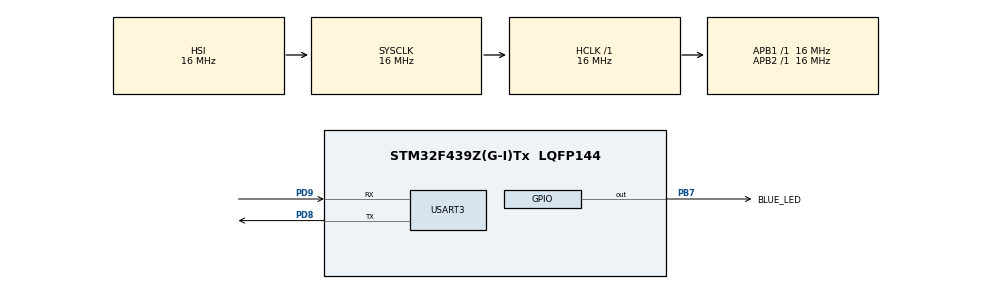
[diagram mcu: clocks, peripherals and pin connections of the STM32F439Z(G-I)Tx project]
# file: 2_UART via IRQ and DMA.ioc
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Dma.Request0=USART3_TX
Dma.USART3_TX.0.Direction=DMA_MEMORY_TO_PERIPH
Dma.USART3_TX.0.FIFOMode=DMA_FIFOMODE_DISABLE
Dma.USART3_TX.0.Instance=DMA1_Stream3
Dma.USART3_TX.0.MemDataAlignment=DMA_MDATAALIGN_BYTE
Dma.USART3_TX.0.MemInc=DMA_MINC_ENABLE
Dma.USART3_TX.0.Mode=DMA_CIRCULAR
Dma.USART3_TX.0.PeriphDataAlignment=DMA_PDATAALIGN_BYTE
Dma.USART3_TX.0.PeriphInc=DMA_PINC_DISABLE
Dma.USART3_TX.0.Priority=DMA_PRIORITY_LOW
Mcu.Family=STM32F4
Mcu.Name=STM32F439Z(G-I)Tx
Mcu.Package=LQFP144
NVIC.DMA1_Stream3_IRQn=true\:0\:0\:false\:false\:true\:false\:true\:true
NVIC.PriorityGroup=NVIC_PRIORITYGROUP_4
NVIC.TIM6_DAC_IRQn=true\:15\:0\:false\:false\:true\:false\:true\:true
NVIC.TimeBase=TIM6_DAC_IRQn
NVIC.TimeBaseIP=TIM6
NVIC.USART3_IRQn=true\:0\:0\:false\:false\:true\:true\:true\:true
PA13.Mode=Trace_Asynchronous_SW
PA13.Signal=SYS_JTMS-SWDIO
PA14.Mode=Trace_Asynchronous_SW
PA14.Signal=SYS_JTCK-SWCLK
PB3.Mode=Trace_Asynchronous_SW
PB3.Signal=SYS_JTDO-SWO
PB7.GPIO_Label=BLUE_LED
PB7.Signal=GPIO_Output
PD8.Mode=Asynchronous
PD8.Signal=USART3_TX
PD9.Mode=Asynchronous
PD9.Signal=USART3_RX
ProjectManager.HeapSize=0x200
ProjectManager.StackSize=0x400
ProjectManager.TargetToolchain=STM32CubeIDE
RCC.AHBFreq_Value=16000000
RCC.APB1Freq_Value=16000000
RCC.APB2Freq_Value=16000000
RCC.CortexFreq_Value=16000000
RCC.HSE_VALUE=25000000
RCC.HSI_VALUE=16000000
RCC.LSE_VALUE=32768
RCC.SYSCLKFreq_VALUE=16000000
RCC.VCOOutputFreq_Value=192000000
USART3.VirtualMode=VM_ASYNC
VP_SYS_VS_tim6.Mode=TIM6
board=custom

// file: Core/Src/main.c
/* USER CODE BEGIN Header */
/**
  ******************************************************************************
  * @file           : main.c
  * @brief          : Main program body
  ******************************************************************************
  * @attention
  *
  * Copyright (c) 2024 STMicroelectronics.
  * All rights reserved.
  *
  * This software is licensed under terms that can be found in the LICENSE file
  * in the root directory of this software component.
  * If no LICENSE file comes with this software, it is provided AS-IS.
  *
  ******************************************************************************
  */
/* USER CODE END Header */
#include "main.h"

UART_HandleTypeDef huart3;
DMA_HandleTypeDef hdma_usart3_tx;

/* USER CODE BEGIN PV */
uint8_t tx_buffer[10240];
uint16_t CB_counter = 0;
uint16_t LOOP_counter = 0;
uint8_t isSent = 1;
uint8_t value = 10;
uint16_t Half_CB_counter = 0;
/* USER CODE END PV */

void SystemClock_Config(void);
static void MX_GPIO_Init(void);
static void MX_DMA_Init(void);
static void MX_USART3_UART_Init(void);

/* USER CODE BEGIN 0 */

/*  Data transfer using Interrupt. Full Transmission complete callback
void HAL_UART_TxCpltCallback(UART_HandleTypeDef *huart){
	CB_counter++;
    isSent = 1;
}
*/

// Data transfer using DMA. Half Transmission complete callback
void HAL_UART_TxHalfCpltCallback(UART_HandleTypeDef *huart){

	for (uint16_t i = 0; i < 5120; i++) {
		tx_buffer[i] = value;
	}
	Half_CB_counter++;
}

// Data transfer using DMA. Full Transmission complete callback
void HAL_UART_TxCpltCallback(UART_HandleTypeDef *huart){

	for (uint16_t i = 5120; i < 10240; i++) {
		tx_buffer[i] = value;
	}
	CB_counter++;
    isSent = 1;
}

/* USER CODE END 0 */

int main(void)
{

  /* MCU Configuration--------------------------------------------------------*/

  /* Reset of all peripherals, Initializes the Flash interface and the Systick. */
  HAL_Init();

  /* Configure the system clock */
  SystemClock_Config();

  /* Initialize all configured peripherals */
  MX_GPIO_Init();
  MX_DMA_Init();
  MX_USART3_UART_Init();
  /* USER CODE BEGIN 2 */
  for(uint16_t i = 0; i < 10240; i++){
	  tx_buffer[i] = i&(0xff);
  }
  /* USER CODE END 2 */

  /* Infinite loop */
  while (1)
  {

    /* USER CODE BEGIN 3 */

	  /* Blocking Mode
	  HAL_UART_Transmit(&huart3, tx_buffer, 10240, HAL_MAX_DELAY);
	  HAL_GPIO_TogglePin(BLUE_LED_GPIO_Port, BLUE_LED_Pin);
	  HAL_Delay(500);
	  */

	  /* Data transfer using Interrupt
      if (isSent){
	  HAL_UART_Transmit_IT(&huart3, tx_buffer, 10240);
	  isSent = 0;
         }
	  HAL_GPIO_TogglePin(BLUE_LED_GPIO_Port, BLUE_LED_Pin);
	  HAL_Delay(500);
	  LOOP_counter++;
	  */

       /* Data Transfer using DMA. DMA Mode = Normal
	     if (isSent){
		  HAL_UART_Transmit_DMA(&huart3, tx_buffer, 10240);
		  isSent = 0;
	         }
		  HAL_GPIO_TogglePin(BLUE_LED_GPIO_Port, BLUE_LED_Pin);
		  HAL_Delay(500);
		  LOOP_counter++;
       */

      /* Data transfer using DMA. DMA Mode = circular
	     if (isSent){
			  HAL_UART_Transmit_DMA(&huart3, tx_buffer, 10240);
			  isSent = 0;
		         }
	     HAL_GPIO_TogglePin(BLUE_LED_GPIO_Port, BLUE_LED_Pin);
		 HAL_Delay(500);
		 LOOP_counter++;

       */
  }
  /* USER CODE END 3 */
}

void SystemClock_Config(void)
{
  RCC_OscInitTypeDef RCC_OscInitStruct = {0};
  RCC_ClkInitTypeDef RCC_ClkInitStruct = {0};

  /** Configure the main internal regulator output voltage
  */
  __HAL_RCC_PWR_CLK_ENABLE();
  __HAL_PWR_VOLTAGESCALING_CONFIG(PWR_REGULATOR_VOLTAGE_SCALE3);

  /** Initializes the RCC Oscillators according to the specified parameters
  * in the RCC_OscInitTypeDef structure.
  */
  RCC_OscInitStruct.OscillatorType = RCC_OSCILLATORTYPE_HSI;
  RCC_OscInitStruct.HSIState = RCC_HSI_ON;
  RCC_OscInitStruct.HSICalibrationValue = RCC_HSICALIBRATION_DEFAULT;
  RCC_OscInitStruct.PLL.PLLState = RCC_PLL_NONE;
  if (HAL_RCC_OscConfig(&RCC_OscInitStruct) != HAL_OK)
  {
    Error_Handler();
  }

  /** Initializes the CPU, AHB and APB buses clocks
  */
  RCC_ClkInitStruct.ClockType = RCC_CLOCKTYPE_HCLK|RCC_CLOCKTYPE_SYSCLK
                              |RCC_CLOCKTYPE_PCLK1|RCC_CLOCKTYPE_PCLK2;
  RCC_ClkInitStruct.SYSCLKSource = RCC_SYSCLKSOURCE_HSI;
  RCC_ClkInitStruct.AHBCLKDivider = RCC_SYSCLK_DIV1;
  RCC_ClkInitStruct.APB1CLKDivider = RCC_HCLK_DIV1;
  RCC_ClkInitStruct.APB2CLKDivider = RCC_HCLK_DIV1;

  if (HAL_RCC_ClockConfig(&RCC_ClkInitStruct, FLASH_LATENCY_0) != HAL_OK)
  {
    Error_Handler();
  }
}

static void MX_USART3_UART_Init(void)
{

  huart3.Instance = USART3;
  huart3.Init.BaudRate = 115200;
  huart3.Init.WordLength = UART_WORDLENGTH_8B;
  huart3.Init.StopBits = UART_STOPBITS_1;
  huart3.Init.Parity = UART_PARITY_NONE;
  huart3.Init.Mode = UART_MODE_TX_RX;
  huart3.Init.HwFlowCtl = UART_HWCONTROL_NONE;
  huart3.Init.OverSampling = UART_OVERSAMPLING_16;
  if (HAL_UART_Init(&huart3) != HAL_OK)
  {
    Error_Handler();
  }

}

static void MX_DMA_Init(void)
{

  /* DMA controller clock enable */
  __HAL_RCC_DMA1_CLK_ENABLE();

  /* DMA interrupt init */
  /* DMA1_Stream3_IRQn interrupt configuration */
  HAL_NVIC_SetPriority(DMA1_Stream3_IRQn, 0, 0);
  HAL_NVIC_EnableIRQ(DMA1_Stream3_IRQn);

}

static void MX_GPIO_Init(void)
{
  GPIO_InitTypeDef GPIO_InitStruct = {0};

  /* GPIO Ports Clock Enable */
  __HAL_RCC_GPIOD_CLK_ENABLE();
  __HAL_RCC_GPIOA_CLK_ENABLE();
  __HAL_RCC_GPIOB_CLK_ENABLE();

  /*Configure GPIO pin Output Level */
  HAL_GPIO_WritePin(BLUE_LED_GPIO_Port, BLUE_LED_Pin, GPIO_PIN_RESET);

  /*Configure GPIO pin : BLUE_LED_Pin */
  GPIO_InitStruct.Pin = BLUE_LED_Pin;
  GPIO_InitStruct.Mode = GPIO_MODE_OUTPUT_PP;
  GPIO_InitStruct.Pull = GPIO_NOPULL;
  GPIO_InitStruct.Speed = GPIO_SPEED_FREQ_LOW;
  HAL_GPIO_Init(BLUE_LED_GPIO_Port, &GPIO_InitStruct);

}

void HAL_TIM_PeriodElapsedCallback(TIM_HandleTypeDef *htim)
{
  if (htim->Instance == TIM6) {
    HAL_IncTick();
  }
}

void Error_Handler(void)
{
  __disable_irq();
  while (1)
  {
  }
}
